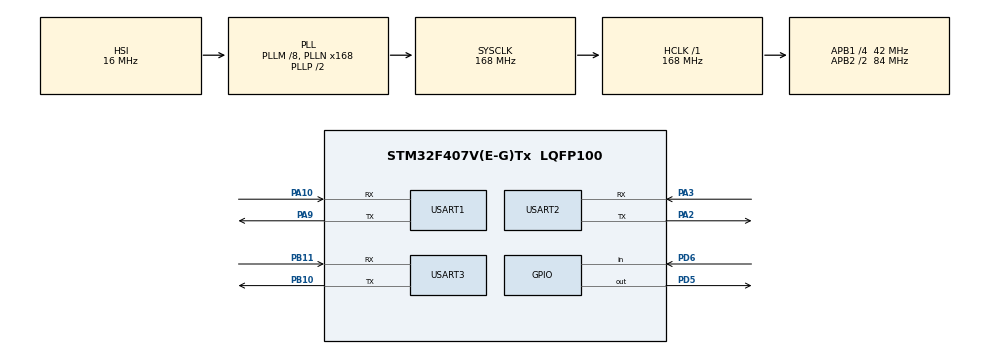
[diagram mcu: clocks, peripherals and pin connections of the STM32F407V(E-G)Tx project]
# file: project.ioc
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Dma.Request0=USART2_RX
Dma.Request1=USART3_RX
Dma.USART2_RX.0.Direction=DMA_PERIPH_TO_MEMORY
Dma.USART2_RX.0.FIFOMode=DMA_FIFOMODE_DISABLE
Dma.USART2_RX.0.Instance=DMA1_Stream5
Dma.USART2_RX.0.MemDataAlignment=DMA_MDATAALIGN_BYTE
Dma.USART2_RX.0.MemInc=DMA_MINC_ENABLE
Dma.USART2_RX.0.Mode=DMA_NORMAL
Dma.USART2_RX.0.PeriphDataAlignment=DMA_PDATAALIGN_BYTE
Dma.USART2_RX.0.PeriphInc=DMA_PINC_DISABLE
Dma.USART2_RX.0.Priority=DMA_PRIORITY_LOW
Dma.USART3_RX.1.Direction=DMA_PERIPH_TO_MEMORY
Dma.USART3_RX.1.FIFOMode=DMA_FIFOMODE_DISABLE
Dma.USART3_RX.1.Instance=DMA1_Stream1
Dma.USART3_RX.1.MemDataAlignment=DMA_MDATAALIGN_BYTE
Dma.USART3_RX.1.MemInc=DMA_MINC_ENABLE
Dma.USART3_RX.1.Mode=DMA_NORMAL
Dma.USART3_RX.1.PeriphDataAlignment=DMA_PDATAALIGN_BYTE
Dma.USART3_RX.1.PeriphInc=DMA_PINC_DISABLE
Dma.USART3_RX.1.Priority=DMA_PRIORITY_LOW
FREERTOS.BinarySemaphores01=check;card
FREERTOS.Queues01=weigherwei,1,float,NULL;pn532rx,16,uint8_t,NULL
FREERTOS.Tasks01=defaultTask,0,128,StartDefaultTask,Default;At_recvtask,-3,128,at_recvtask,Default;At_SendTask,-3,128,at_sendtask,Default;NfcRxTask,0,128,nfcrxtask,Default;NfcTxTask,-3,128,nfctxtask,Default
FREERTOS.Timers01=myTimer01,Callback01,osTimerOnce,Default
FREERTOS.configUSE_TIMERS=1
Mcu.Family=STM32F4
Mcu.Name=STM32F407V(E-G)Tx
Mcu.Package=LQFP100
NVIC.DMA1_Stream1_IRQn=true\:5\:0\:false\:false\:true\:true
NVIC.DMA1_Stream5_IRQn=true\:5\:0\:false\:false\:true\:true
NVIC.PriorityGroup=NVIC_PRIORITYGROUP_4
NVIC.TIM6_DAC_IRQn=true\:5\:0\:false\:false\:true\:true
NVIC.USART1_IRQn=true\:5\:0\:false\:false\:true\:true
NVIC.USART2_IRQn=true\:5\:0\:false\:false\:true\:true
NVIC.USART3_IRQn=true\:5\:0\:false\:false\:true\:true
PA10.Mode=Asynchronous
PA10.Signal=USART1_RX
PA2.Mode=Asynchronous
PA2.Signal=USART2_TX
PA3.Mode=Asynchronous
PA3.Signal=USART2_RX
PA9.Mode=Asynchronous
PA9.Signal=USART1_TX
PB10.Mode=Asynchronous
PB10.Signal=USART3_TX
PB11.Mode=Asynchronous
PB11.Signal=USART3_RX
PD5.Signal=GPIO_Output
PD6.Signal=GPIO_Input
PH0-OSC_IN.Mode=HSE-External-Oscillator
PH0-OSC_IN.Signal=RCC_OSC_IN
PH1-OSC_OUT.Mode=HSE-External-Oscillator
PH1-OSC_OUT.Signal=RCC_OSC_OUT
ProjectManager.HeapSize=0x200
ProjectManager.StackSize=0x400
ProjectManager.TargetToolchain=EWARM
RCC.48MHZClocksFreq_Value=84000000
RCC.AHBFreq_Value=168000000
RCC.APB1CLKDivider=RCC_HCLK_DIV4
RCC.APB1Freq_Value=42000000
RCC.APB1TimFreq_Value=84000000
RCC.APB2CLKDivider=RCC_HCLK_DIV2
RCC.APB2Freq_Value=84000000
RCC.APB2TimFreq_Value=168000000
RCC.CortexFreq_Value=168000000
RCC.HCLKFreq_Value=168000000
RCC.HSE_VALUE=8000000
RCC.HSI_VALUE=16000000
RCC.LSE_VALUE=32768
RCC.PLLM=8
RCC.PLLN=168
RCC.SYSCLKFreq_VALUE=168000000
RCC.SYSCLKSource=RCC_SYSCLKSOURCE_PLLCLK
RCC.VCOOutputFreq_Value=336000000
VP_FREERTOS_VS_ENABLE.Mode=Enabled
VP_TIM6_VS_ClockSourceINT.Mode=Enable_Timer
board=project

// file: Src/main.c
/**
  ******************************************************************************
  * File Name          : main.c
  * Description        : Main program body
  ******************************************************************************
  *
  * COPYRIGHT(c) 2016 STMicroelectronics
  *
  * Redistribution and use in source and binary forms, with or without modification,
  * are permitted provided that the following conditions are met:
  *   1. Redistributions of source code must retain the above copyright notice,
  *      this list of conditions and the following disclaimer.
  *   2. Redistributions in binary form must reproduce the above copyright notice,
  *      this list of conditions and the following disclaimer in the documentation
  *      and/or other materials provided with the distribution.
  *   3. Neither the name of STMicroelectronics nor the names of its contributors
  *      may be used to endorse or promote products derived from this software
  *      without specific prior written permission.
  *
  * THIS SOFTWARE IS PROVIDED BY THE COPYRIGHT HOLDERS AND CONTRIBUTORS "AS IS"
  * AND ANY EXPRESS OR IMPLIED WARRANTIES, INCLUDING, BUT NOT LIMITED TO, THE
  * IMPLIED WARRANTIES OF MERCHANTABILITY AND FITNESS FOR A PARTICULAR PURPOSE ARE
  * DISCLAIMED. IN NO EVENT SHALL THE COPYRIGHT HOLDER OR CONTRIBUTORS BE LIABLE
  * FOR ANY DIRECT, INDIRECT, INCIDENTAL, SPECIAL, EXEMPLARY, OR CONSEQUENTIAL
  * DAMAGES (INCLUDING, BUT NOT LIMITED TO, PROCUREMENT OF SUBSTITUTE GOODS OR
  * SERVICES; LOSS OF USE, DATA, OR PROFITS; OR BUSINESS INTERRUPTION) HOWEVER
  * CAUSED AND ON ANY THEORY OF LIABILITY, WHETHER IN CONTRACT, STRICT LIABILITY,
  * OR TORT (INCLUDING NEGLIGENCE OR OTHERWISE) ARISING IN ANY WAY OUT OF THE USE
  * OF THIS SOFTWARE, EVEN IF ADVISED OF THE POSSIBILITY OF SUCH DAMAGE.
  *
  ******************************************************************************
  */
#include "stm32f4xx_hal.h"
#include "cmsis_os.h"

/* USER CODE BEGIN Includes */
#include "uart.h"
#include "HX711.h"
#include "pn532.h"
/* USER CODE END Includes */

TIM_HandleTypeDef htim6;

UART_HandleTypeDef huart1;
UART_HandleTypeDef huart2;
UART_HandleTypeDef huart3;
DMA_HandleTypeDef hdma_usart2_rx;
DMA_HandleTypeDef hdma_usart3_rx;

osThreadId defaultTaskHandle;
osThreadId At_recvtaskHandle;
osThreadId At_SendTaskHandle;
osThreadId NfcRxTaskHandle;
osThreadId NfcTxTaskHandle;
osMessageQId weigherweiHandle;
osMessageQId pn532rxHandle;
osTimerId myTimer01Handle;
osSemaphoreId checkHandle;
osSemaphoreId cardHandle;

/* USER CODE BEGIN PV */
/* Private variables ---------------------------------------------------------*/

/* USER CODE END PV */

void SystemClock_Config(void);
void Error_Handler(void);
static void MX_GPIO_Init(void);
static void MX_DMA_Init(void);
static void MX_USART1_UART_Init(void);
static void MX_USART2_UART_Init(void);
static void MX_TIM6_Init(void);
static void MX_USART3_UART_Init(void);
void StartDefaultTask(void const * argument);
void at_recvtask(void const * argument);
void at_sendtask(void const * argument);
void nfcrxtask(void const * argument);
void nfctxtask(void const * argument);
void Callback01(void const * argument);

/* USER CODE BEGIN PFP */
/* Private function prototypes -----------------------------------------------*/

/* USER CODE END PFP */

int main(void)
{

  /* MCU Configuration----------------------------------------------------------*/

  /* Reset of all peripherals, Initializes the Flash interface and the Systick. */
  HAL_Init();

  /* Configure the system clock */
  SystemClock_Config();

  /* Initialize all configured peripherals */
  MX_GPIO_Init();
  MX_DMA_Init();
  MX_USART1_UART_Init();
  MX_USART2_UART_Init();
  MX_TIM6_Init();
  MX_USART3_UART_Init();

  /* Create the semaphores(s) */
  /* definition and creation of check */
  osSemaphoreDef(check);
  checkHandle = osSemaphoreCreate(osSemaphore(check), 1);

  /* definition and creation of card */
  osSemaphoreDef(card);
  cardHandle = osSemaphoreCreate(osSemaphore(card), 1);

  /* Create the timer(s) */
  /* definition and creation of myTimer01 */
  osTimerDef(myTimer01, Callback01);
  myTimer01Handle = osTimerCreate(osTimer(myTimer01), osTimerOnce, NULL);

  /* Create the thread(s) */
  /* definition and creation of defaultTask */
  osThreadDef(defaultTask, StartDefaultTask, osPriorityNormal, 0, 128);
  defaultTaskHandle = osThreadCreate(osThread(defaultTask), NULL);

  /* definition and creation of At_recvtask */
  osThreadDef(At_recvtask, at_recvtask, osPriorityIdle, 0, 128);
  At_recvtaskHandle = osThreadCreate(osThread(At_recvtask), NULL);

  /* definition and creation of At_SendTask */
  osThreadDef(At_SendTask, at_sendtask, osPriorityIdle, 0, 128);
  At_SendTaskHandle = osThreadCreate(osThread(At_SendTask), NULL);

  /* definition and creation of NfcRxTask */
  osThreadDef(NfcRxTask, nfcrxtask, osPriorityNormal, 0, 128);
  NfcRxTaskHandle = osThreadCreate(osThread(NfcRxTask), NULL);

  /* definition and creation of NfcTxTask */
  osThreadDef(NfcTxTask, nfctxtask, osPriorityIdle, 0, 128);
  NfcTxTaskHandle = osThreadCreate(osThread(NfcTxTask), NULL);

  /* Create the queue(s) */
  /* definition and creation of weigherwei */
  osMessageQDef(weigherwei, 1, float);
  weigherweiHandle = osMessageCreate(osMessageQ(weigherwei), NULL);

  /* definition and creation of pn532rx */
  osMessageQDef(pn532rx, 16, uint8_t);
  pn532rxHandle = osMessageCreate(osMessageQ(pn532rx), NULL);

  /* Start scheduler */
  osKernelStart();

  /* We should never get here as control is now taken by the scheduler */

  /* Infinite loop */
  while (1)
  {

  }

}

/** System Clock Configuration
*/
void SystemClock_Config(void)
{

  RCC_OscInitTypeDef RCC_OscInitStruct;
  RCC_ClkInitTypeDef RCC_ClkInitStruct;

  __HAL_RCC_PWR_CLK_ENABLE();

  __HAL_PWR_VOLTAGESCALING_CONFIG(PWR_REGULATOR_VOLTAGE_SCALE1);

  RCC_OscInitStruct.OscillatorType = RCC_OSCILLATORTYPE_HSI;
  RCC_OscInitStruct.HSIState = RCC_HSI_ON;
  RCC_OscInitStruct.HSICalibrationValue = 16;
  RCC_OscInitStruct.PLL.PLLState = RCC_PLL_ON;
  RCC_OscInitStruct.PLL.PLLSource = RCC_PLLSOURCE_HSI;
  RCC_OscInitStruct.PLL.PLLM = 8;
  RCC_OscInitStruct.PLL.PLLN = 168;
  RCC_OscInitStruct.PLL.PLLP = RCC_PLLP_DIV2;
  RCC_OscInitStruct.PLL.PLLQ = 4;
  if (HAL_RCC_OscConfig(&RCC_OscInitStruct) != HAL_OK)
  {
    Error_Handler();
  }

  RCC_ClkInitStruct.ClockType = RCC_CLOCKTYPE_HCLK|RCC_CLOCKTYPE_SYSCLK
                              |RCC_CLOCKTYPE_PCLK1|RCC_CLOCKTYPE_PCLK2;
  RCC_ClkInitStruct.SYSCLKSource = RCC_SYSCLKSOURCE_PLLCLK;
  RCC_ClkInitStruct.AHBCLKDivider = RCC_SYSCLK_DIV1;
  RCC_ClkInitStruct.APB1CLKDivider = RCC_HCLK_DIV4;
  RCC_ClkInitStruct.APB2CLKDivider = RCC_HCLK_DIV2;
  if (HAL_RCC_ClockConfig(&RCC_ClkInitStruct, FLASH_LATENCY_5) != HAL_OK)
  {
    Error_Handler();
  }

  HAL_SYSTICK_Config(HAL_RCC_GetHCLKFreq()/1000);

  HAL_SYSTICK_CLKSourceConfig(SYSTICK_CLKSOURCE_HCLK);

  /* SysTick_IRQn interrupt configuration */
  HAL_NVIC_SetPriority(SysTick_IRQn, 15, 0);
}

/* TIM6 init function */
static void MX_TIM6_Init(void)
{

  TIM_MasterConfigTypeDef sMasterConfig;

  htim6.Instance = TIM6;
  htim6.Init.Prescaler = 0;
  htim6.Init.CounterMode = TIM_COUNTERMODE_UP;
  htim6.Init.Period = 0;
  if (HAL_TIM_Base_Init(&htim6) != HAL_OK)
  {
    Error_Handler();
  }

  sMasterConfig.MasterOutputTrigger = TIM_TRGO_RESET;
  sMasterConfig.MasterSlaveMode = TIM_MASTERSLAVEMODE_DISABLE;
  if (HAL_TIMEx_MasterConfigSynchronization(&htim6, &sMasterConfig) != HAL_OK)
  {
    Error_Handler();
  }

}

/* USART1 init function */
static void MX_USART1_UART_Init(void)
{

  huart1.Instance = USART1;
  huart1.Init.BaudRate = 115200;
  huart1.Init.WordLength = UART_WORDLENGTH_8B;
  huart1.Init.StopBits = UART_STOPBITS_1;
  huart1.Init.Parity = UART_PARITY_NONE;
  huart1.Init.Mode = UART_MODE_TX_RX;
  huart1.Init.HwFlowCtl = UART_HWCONTROL_NONE;
  huart1.Init.OverSampling = UART_OVERSAMPLING_16;
  if (HAL_UART_Init(&huart1) != HAL_OK)
  {
    Error_Handler();
  }

}

/* USART2 init function */
static void MX_USART2_UART_Init(void)
{

  huart2.Instance = USART2;
  huart2.Init.BaudRate = 115200;
  huart2.Init.WordLength = UART_WORDLENGTH_8B;
  huart2.Init.StopBits = UART_STOPBITS_1;
  huart2.Init.Parity = UART_PARITY_NONE;
  huart2.Init.Mode = UART_MODE_TX_RX;
  huart2.Init.HwFlowCtl = UART_HWCONTROL_NONE;
  huart2.Init.OverSampling = UART_OVERSAMPLING_16;
  if (HAL_UART_Init(&huart2) != HAL_OK)
  {
    Error_Handler();
  }

}

/* USART3 init function */
static void MX_USART3_UART_Init(void)
{

  huart3.Instance = USART3;
  huart3.Init.BaudRate = 115200;
  huart3.Init.WordLength = UART_WORDLENGTH_8B;
  huart3.Init.StopBits = UART_STOPBITS_1;
  huart3.Init.Parity = UART_PARITY_NONE;
  huart3.Init.Mode = UART_MODE_TX_RX;
  huart3.Init.HwFlowCtl = UART_HWCONTROL_NONE;
  huart3.Init.OverSampling = UART_OVERSAMPLING_16;
  if (HAL_UART_Init(&huart3) != HAL_OK)
  {
    Error_Handler();
  }

}

static void MX_DMA_Init(void)
{
  /* DMA controller clock enable */
  __HAL_RCC_DMA1_CLK_ENABLE();

  /* DMA interrupt init */
  /* DMA1_Stream1_IRQn interrupt configuration */
  HAL_NVIC_SetPriority(DMA1_Stream1_IRQn, 5, 0);
  HAL_NVIC_EnableIRQ(DMA1_Stream1_IRQn);
  /* DMA1_Stream5_IRQn interrupt configuration */
  HAL_NVIC_SetPriority(DMA1_Stream5_IRQn, 5, 0);
  HAL_NVIC_EnableIRQ(DMA1_Stream5_IRQn);

}

/** Configure pins as
        * Analog
        * Input
        * Output
        * EVENT_OUT
        * EXTI
*/
static void MX_GPIO_Init(void)
{

  GPIO_InitTypeDef GPIO_InitStruct;

  /* GPIO Ports Clock Enable */
  __HAL_RCC_GPIOH_CLK_ENABLE();
  __HAL_RCC_GPIOA_CLK_ENABLE();
  __HAL_RCC_GPIOB_CLK_ENABLE();
  __HAL_RCC_GPIOD_CLK_ENABLE();

  /*Configure GPIO pin Output Level */
  HAL_GPIO_WritePin(GPIOD, GPIO_PIN_5, GPIO_PIN_RESET);

  /*Configure GPIO pin : PD5 */
  GPIO_InitStruct.Pin = GPIO_PIN_5;
  GPIO_InitStruct.Mode = GPIO_MODE_OUTPUT_PP;
  GPIO_InitStruct.Pull = GPIO_NOPULL;
  GPIO_InitStruct.Speed = GPIO_SPEED_FREQ_LOW;
  HAL_GPIO_Init(GPIOD, &GPIO_InitStruct);

  /*Configure GPIO pin : PD6 */
  GPIO_InitStruct.Pin = GPIO_PIN_6;
  GPIO_InitStruct.Mode = GPIO_MODE_INPUT;
  GPIO_InitStruct.Pull = GPIO_NOPULL;
  HAL_GPIO_Init(GPIOD, &GPIO_InitStruct);

}

/* StartDefaultTask function */
void StartDefaultTask(void const * argument)
{

  /* USER CODE BEGIN 5 */
  weight_task();
  /* Infinite loop */
  for(;;)
  {
    osDelay(1000);
  }
  /* USER CODE END 5 */
}

/* at_recvtask function */
void at_recvtask(void const * argument)
{
  /* USER CODE BEGIN at_recvtask */
  at_recv_task();
  /* Infinite loop */
  for(;;)
  {
    osDelay(1);
  }
  /* USER CODE END at_recvtask */
}

/* at_sendtask function */
void at_sendtask(void const * argument)
{
  /* USER CODE BEGIN at_sendtask */
  at_send_task();
  /* Infinite loop */
  for(;;)
  {
    osDelay(1);
  }
  /* USER CODE END at_sendtask */
}

/* nfcrxtask function */
void nfcrxtask(void const * argument)
{
  /* USER CODE BEGIN nfcrxtask */
  nfc_rx_task();
  /* Infinite loop */
  for(;;)
  {
    osDelay(1);
  }
  /* USER CODE END nfcrxtask */
}

/* nfctxtask function */
void nfctxtask(void const * argument)
{
  /* USER CODE BEGIN nfctxtask */
  nfc_tx_task();
  /* Infinite loop */
  for(;;)
  {
    osDelay(1);
  }
  /* USER CODE END nfctxtask */
}

/* Callback01 function */
void Callback01(void const * argument)
{
  /* USER CODE BEGIN Callback01 */
  //uint8_t tmp=0x55;
  //HAL_UART_Transmit(&huart1, &tmp,1, 100);
  /* USER CODE END Callback01 */
}

void Error_Handler(void)
{
  while(1)
  {
  }
}

/************************ (C) COPYRIGHT STMicroelectronics *****END OF FILE****/
